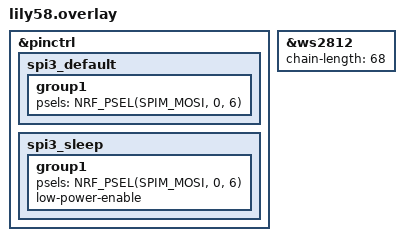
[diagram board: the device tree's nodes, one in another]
&pinctrl {
    spi3_default: spi3_default {
        group1 {
            psels = <NRF_PSEL(SPIM_MOSI, 0, 6)>; // Prüfe, ob Data-Pin P0.06 ist (Standard bei Lily58)
        };
    };
    
    spi3_sleep: spi3_sleep {
        group1 {
            psels = <NRF_PSEL(SPIM_MOSI, 0, 6)>;
            low-power-enable;
        };
    };
};

&ws2812 {
    /* Anzahl der LEDs: 
       58 (Tasten) + ca. 10 (Underglow) = 68. 
       Setze diesen Wert hoch genug für dein Kit. 
    */
    chain-length = <68>; 
};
